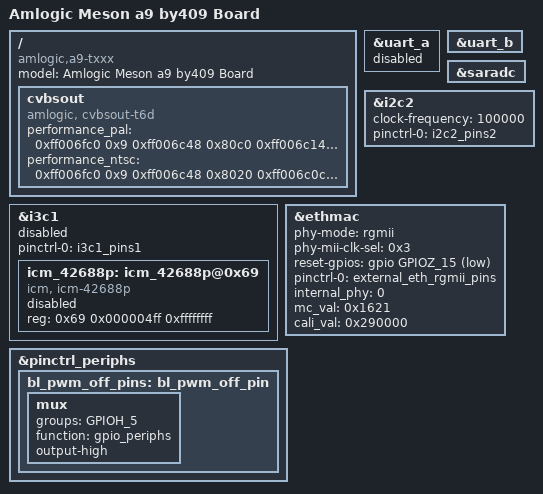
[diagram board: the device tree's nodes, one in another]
// SPDX-License-Identifier: (GPL-2.0+ OR MIT)
/*
 * Copyright (c) 2019 Amlogic, Inc. All rights reserved.
 */

/dts-v1/;

#include "amlogic/meson-a9-by409.dtsi"
#include "amlogic/meson-a9-panel.dtsi"

/ {
	compatible =  "amlogic,a9-txxx", "amlogic,meson-a9";
	model = "Amlogic Meson a9 by409 Board";
cvbsout {
		compatible = "amlogic, cvbsout-t6d";
		status = "okay";

		/* performance: reg_address, reg_value */
		/* t6d */
		/* pal default Matrx625 CTCC value */
		performance_pal = <0xff006fc0  0x9 /* 0x1bf0 << 2 + 0xff000000 */
			0xff006c48  0x80c0 /* 0x1b12 */
			0xff006c14  0xf7 /* 0x1b05 */
			0xff006d58  0x333 /* 0x1b56 */
			0xff007164  0xf25c /* 0x1c59 */
			0xffff  0x0>; /* ending flag */
		performance_ntsc = <0xff006fc0  0x9 /* 0x1bf0 << 2 + 0xff000000 */
			0xff006c48  0x8020 /* 0x1b12 */
			0xff006c0c  0x0 /* 0x1b03 */
			0xff006c10  0x0 /* 0x1b04 */
			0xff006c14  0x0 /* 0x1b05 */
			0xff006d58  0x333 /* 0x1b56 */
			0xff007164  0xf850 /* 0x1c59 */
			0xffff  0x0>; /* ending flag */
	};
};

/* This UART is brought out to the DB9 connector */
&uart_a {
	status = "disable";
};

&uart_b {
	status = "okay";
};

&saradc {
	status = "okay";
};

/* lcd i2c */
&i2c2 {
	status= "okay";
	clock-frequency = <100000>;
	pinctrl-names = "default";
	pinctrl-0 = <&i2c2_pins2>;
};

&i3c1 {
	status= "disabled";
	pinctrl-names = "default";
	pinctrl-0 = <&i3c1_pins1>;

	icm_42688p: icm_42688p@0x69 {
		//32bit static addr + 64bit PID
		reg = <0x69 0x000004ff 0xffffffff>;
		compatible = "icm, icm-42688p";
		status = "disabled";
	};
};

&ethmac {
	status = "okay";
	phy-mode = "rgmii";
	phy-mii-clk-sel = <0x3>;
	reset-gpios = <&gpio GPIOZ_15 (GPIO_ACTIVE_LOW | GPIO_OPEN_DRAIN)>;
	pinctrl-names = "external_eth_rgmii_pins";
	pinctrl-0 = <&external_eth_rgmii_pins>;
	internal_phy = <0>;
	mc_val = <0x1621>;
	cali_val = <0x290000>;
};

&pinctrl_periphs {
	bl_pwm_off_pins:bl_pwm_off_pin {
		mux {
			groups = "GPIOH_5";
			function = "gpio_periphs";
			output-high;
		};
	};
}; /* end of pinctrl_periphs */
